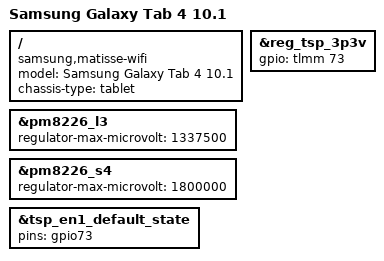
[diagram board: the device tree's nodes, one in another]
// SPDX-License-Identifier: BSD-3-Clause
/*
 * Copyright (c) 2022, Matti Lehtimäki <matti.lehtimaki@gmail.com>
 */

/dts-v1/;

#include "qcom-msm8226.dtsi"
#include "qcom-msm8226-samsung-matisse-common.dtsi"

/ {
	model = "Samsung Galaxy Tab 4 10.1";
	compatible = "samsung,matisse-wifi", "qcom,apq8026";
	chassis-type = "tablet";
};

&pm8226_l3 {
	regulator-max-microvolt = <1337500>;
};

&pm8226_s4 {
	regulator-max-microvolt = <1800000>;
};

&reg_tsp_3p3v {
	gpio = <&tlmm 73 GPIO_ACTIVE_HIGH>;
};

&tsp_en1_default_state {
	pins = "gpio73";
};
